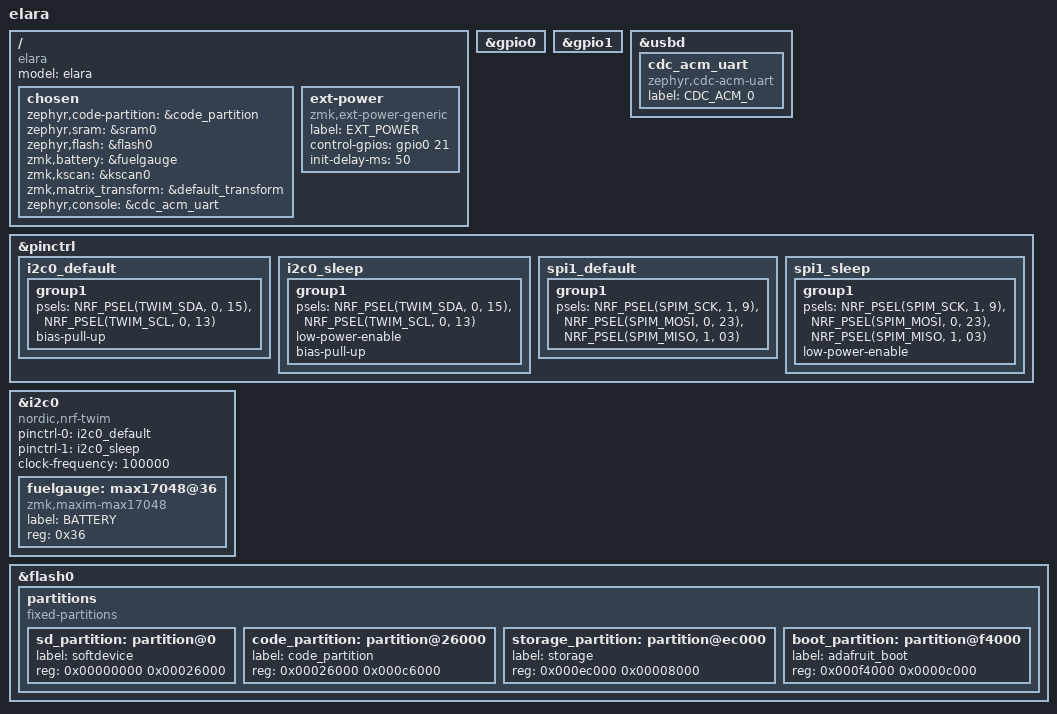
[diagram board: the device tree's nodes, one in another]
/*
 * Copyright (c) 2020 The ZMK Contributors
 *
 * SPDX-License-Identifier: MIT
 */

/dts-v1/;
#include <nordic/nrf52840_qiaa.dtsi>
#include <dt-bindings/zmk/matrix_transform.h>

/ {
	model = "elara";
	compatible = "elara";

	chosen {
		zephyr,code-partition = &code_partition;
		zephyr,sram = &sram0;
		zephyr,flash = &flash0;
		zmk,battery = &fuelgauge;
		zmk,kscan = &kscan0;
		zmk,matrix_transform = &default_transform;
		zephyr,console = &cdc_acm_uart; 
	};

	ext-power {
		compatible = "zmk,ext-power-generic";
		label = "EXT_POWER";
		control-gpios = <&gpio0 21 GPIO_ACTIVE_HIGH>;
		init-delay-ms = <50>;
	};

};

&gpio0 {
	status = "okay";
};

&gpio1 {
	status = "okay";
};

&usbd {
    status = "okay";
    cdc_acm_uart: cdc_acm_uart {
        compatible = "zephyr,cdc-acm-uart";
        label = "CDC_ACM_0";
    }; 
};

&pinctrl {
	i2c0_default: i2c0_default {
			group1 {
					psels = <NRF_PSEL(TWIM_SDA, 0, 15)>,
						<NRF_PSEL(TWIM_SCL, 0, 13)>;
				        bias-pull-up;

			};
	};

	i2c0_sleep: i2c0_sleep {
			group1 {
					psels = <NRF_PSEL(TWIM_SDA, 0, 15)>,
						<NRF_PSEL(TWIM_SCL, 0, 13)>;
					low-power-enable;
       					bias-pull-up;
			};
	};

    spi1_default: spi1_default {
        group1 {
            psels = <NRF_PSEL(SPIM_SCK, 1, 9)>,
                <NRF_PSEL(SPIM_MOSI, 0, 23)>,
                <NRF_PSEL(SPIM_MISO, 1, 03)>;
        };
    };

    spi1_sleep: spi1_sleep {
        group1 {
            psels = <NRF_PSEL(SPIM_SCK, 1, 9)>,
                <NRF_PSEL(SPIM_MOSI, 0, 23)>,
                <NRF_PSEL(SPIM_MISO, 1, 03)>;
            low-power-enable;
        };
    };
};

&i2c0 {
	status = "okay";
	compatible = "nordic,nrf-twim";
	pinctrl-0 = <&i2c0_default>;
    pinctrl-1 = <&i2c0_sleep>;
    pinctrl-names = "default", "sleep";
	clock-frequency = <100000>;

	fuelgauge: max17048@36 {
		compatible = "zmk,maxim-max17048";
		label = "BATTERY";
		reg = <0x36>;
	};
};

&flash0 {
	/*
	 * For more information, see:
	 * http://docs.zephyrproject.org/latest/devices/dts/flash_partitions.html
	 */
	partitions {
		compatible = "fixed-partitions";
		#address-cells = <1>;
		#size-cells = <1>;

		sd_partition: partition@0 {
			label = "softdevice";
			reg = <0x00000000 0x00026000>;
		};
		code_partition: partition@26000 {
			label = "code_partition";
			reg = <0x00026000 0x000c6000>;
		};

		/*
		 * The flash starting at 0x000ec000 and ending at
		 * 0x000f3fff is reserved for use by the application.
		 */

		/*
		 * Storage partition will be used by FCB/LittleFS/NVS
		 * if enabled.
		 */
		storage_partition: partition@ec000 {
			label = "storage";
			reg = <0x000ec000 0x00008000>;
		};

		boot_partition: partition@f4000 {
			label = "adafruit_boot";
			reg = <0x000f4000 0x0000c000>;
		};
	};
};
